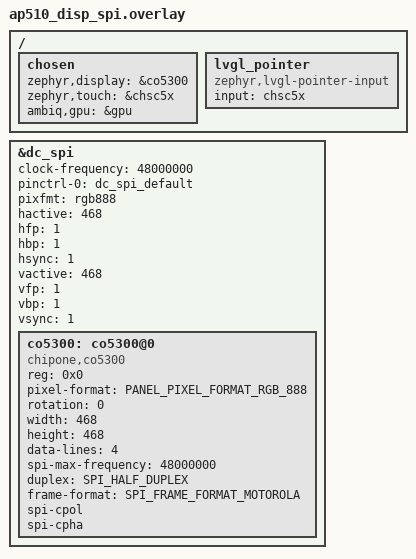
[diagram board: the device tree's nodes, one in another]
/*
 * Copyright (c) 2025 Ambiq Micro Inc.
 *
 * SPDX-License-Identifier: Apache-2.0
 */
#include <apollo510/ambiq-apollo510-pinmux.h>
#include <zephyr/dt-bindings/spi/spi.h>
#include <zephyr/dt-bindings/display/panel.h>
#include <zephyr/dt-bindings/i2c/i2c.h>

/ {
	chosen {
		zephyr,display = &co5300;
		zephyr,touch = &chsc5x;
		ambiq,gpu = &gpu;
	};

	lvgl_pointer {
		compatible = "zephyr,lvgl-pointer-input";
		input = <&chsc5x>;
	};
};

&dc_spi {
	status = "okay";
	clock-frequency = <48000000>;
	/*disp-te;*/
	pinctrl-0 = <&dc_spi_default>;
	pinctrl-names = "default";
	pixfmt = "rgb888";
	hactive = <468>;	/*its value depends on display size*/
	hfp = <1>;	/*Please use this recommended value.*/
	hbp = <1>;	/*Please use this recommended value.*/
	hsync = <1>;	/*Please use this recommended value.*/
	vactive = <468>;	/*its value depends on display size*/
	vfp = <1>;	/*Please use this recommended value.*/
	vbp = <1>;	/*Please use this recommended value.*/
	vsync = <1>;	/*Please use this recommended value.*/

	co5300: co5300@0 {
		status = "okay";
		compatible = "chipone,co5300";
		reg = <0x0>;
		pixel-format = <PANEL_PIXEL_FORMAT_RGB_888>;
		rotation = <0>;
		width = <468>;	/*Its value should be an integer multiple of 4.*/
		height = <468>;

		data-lines = <4>;
		spi-max-frequency = <48000000>;
		duplex = <SPI_HALF_DUPLEX>;
		frame-format = <SPI_FRAME_FORMAT_MOTOROLA>;
		spi-cpol;
		spi-cpha;
		/*spi-hold-cs;*/
	};
};
